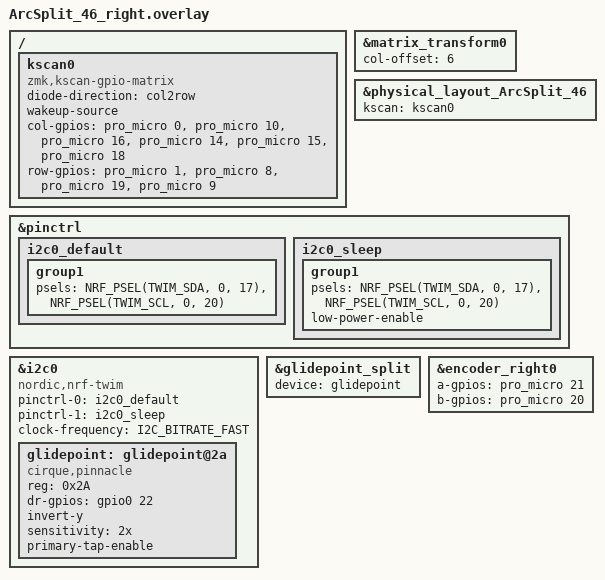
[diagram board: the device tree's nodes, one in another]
#include "ArcSplit_46.dtsi"

/ {
    kscan0: kscan0 {
        compatible = "zmk,kscan-gpio-matrix";
        diode-direction = "col2row";
        wakeup-source;

        col-gpios
            = <&pro_micro 0 GPIO_ACTIVE_HIGH>
            , <&pro_micro 10 GPIO_ACTIVE_HIGH>
            , <&pro_micro 16 GPIO_ACTIVE_HIGH>
            , <&pro_micro 14 GPIO_ACTIVE_HIGH>
            , <&pro_micro 15 GPIO_ACTIVE_HIGH>
            , <&pro_micro 18 GPIO_ACTIVE_HIGH>
            ;

        row-gpios
            = <&pro_micro 1 (GPIO_ACTIVE_HIGH | GPIO_PULL_DOWN)>
            , <&pro_micro 8 (GPIO_ACTIVE_HIGH | GPIO_PULL_DOWN)>
            , <&pro_micro 19 (GPIO_ACTIVE_HIGH | GPIO_PULL_DOWN)>
            , <&pro_micro 9 (GPIO_ACTIVE_HIGH | GPIO_PULL_DOWN)>
            ;
    };
};

&matrix_transform0 {
    col-offset = <6>;
};

&physical_layout_ArcSplit_46 {
    kscan = <&kscan0>;
};


// pin control for i2c0
// - SDA on D2
// - SCL on D3
&pinctrl {
    /* configuration for i2c0 device, default state */
    i2c0_default: i2c0_default {
        group1 {
            psels = <NRF_PSEL(TWIM_SDA, 0, 17)>,
                    <NRF_PSEL(TWIM_SCL, 0, 20)>;
        };
    };
    /* configuration for i2c0 device, sleep state */
    i2c0_sleep: i2c0_sleep {
        group1 {
            psels = <NRF_PSEL(TWIM_SDA, 0, 17)>,
                    <NRF_PSEL(TWIM_SCL, 0, 20)>;
            low-power-enable;
        };
    };
};

&i2c0 {
    compatible = "nordic,nrf-twim";
    status = "okay";
    pinctrl-0 = <&i2c0_default>;
    pinctrl-1 = <&i2c0_sleep>;
    pinctrl-names = "default", "sleep";
    clock-frequency = <I2C_BITRATE_FAST>;

    glidepoint: glidepoint@2a {
        status = "okay";
        compatible = "cirque,pinnacle";
        reg = <0x2A>;
        dr-gpios = <&gpio0 22 (GPIO_ACTIVE_HIGH)>;
        invert-y;
        sensitivity = "2x";
        primary-tap-enable;
    };
};

&glidepoint_split {
    device = <&glidepoint>;
};

&encoder_right0 {
    a-gpios = <&pro_micro 21 (GPIO_ACTIVE_HIGH | GPIO_PULL_UP)>;
    b-gpios = <&pro_micro 20 (GPIO_ACTIVE_HIGH | GPIO_PULL_UP)>;
    status = "okay";
};


